# m52363b register map
Vendor: Elmos Semiconductor SE; Series: Integrated Driver; File version: 1.0
CPU: CM23 r1p0, little endian, MPU, no FPU, VTOR, 2 interrupt priority bits, 13 interrupts
Registers are 16-bit, read-write, reset 0x0 unless marked. A register's access mark holds for its fields unless they carry their own. Offsets are from the block's base; [hi:lo] are bit positions; 'fields as' and 'values as' point back to an identical list.

## SYS_STATE — System state module
Base 0x41000400
0x00 VTOR 32-bit reset 0x2000000
  [31:0] val — val bitfield
0x08 TEST_MODE 32-bit ro
  [0] state — state bitfield
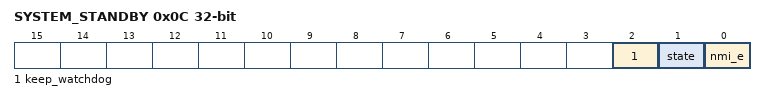
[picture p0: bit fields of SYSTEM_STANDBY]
0x0C SYSTEM_STANDBY 32-bit
  [2] keep_watchdog — keep_watchdog bitfield
  [1] state ro — state bitfield
  [0] nmi_e — nmi_e bitfield
0x10 METAL_CHANGE_CODING 32-bit ro
  [7:0] val — val bitfield
0x14 UDIN 32-bit
  [31:0] val — val bitfield
0x18 DEVICE_ID_L 32-bit ro
  [31:0] val — val bitfield
0x1C DEVICE_ID_H 32-bit ro
  [31:0] val — val bitfield

## RESET_CTRL — Reset control module
Base 0x41000500
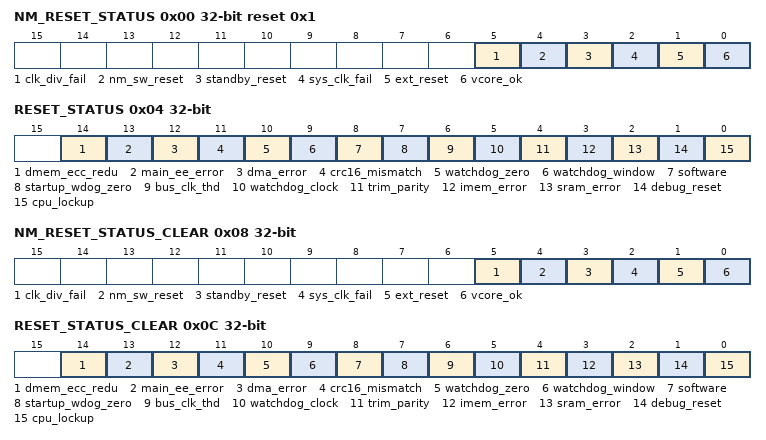
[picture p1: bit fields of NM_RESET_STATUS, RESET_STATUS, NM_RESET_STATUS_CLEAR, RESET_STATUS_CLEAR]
0x00 NM_RESET_STATUS 32-bit ro reset 0x1
  [5] clk_div_fail — clk_div_fail bitfield
  [4] nm_sw_reset — nm_sw_reset bitfield
  [3] standby_reset — standby_reset bitfield
  [2] sys_clk_fail — sys_clk_fail bitfield
  [1] ext_reset — ext_reset bitfield
  [0] vcore_ok — vcore_ok bitfield
0x04 RESET_STATUS 32-bit ro
  [14] dmem_ecc_redu — dmem_ecc_redu bitfield
  [13] main_ee_error — main_ee_error bitfield
  [12] dma_error — dma_error bitfield
  [11] crc16_mismatch — crc16_mismatch bitfield
  [10] watchdog_zero — watchdog_zero bitfield
  [9] watchdog_window — watchdog_window bitfield
  [8] software — software bitfield
  [7] startup_wdog_zero — startup_wdog_zero bitfield
  [6] bus_clk_thd — bus_clk_thd bitfield
  [5] watchdog_clock — watchdog_clock bitfield
  [4] trim_parity — trim_parity bitfield
  [3] imem_error — imem_error bitfield
  [2] sram_error — sram_error bitfield
  [1] debug_reset — debug_reset bitfield
  [0] cpu_lockup — cpu_lockup bitfield
0x08 NM_RESET_STATUS_CLEAR 32-bit wo reset not defined
  fields as NM_RESET_STATUS
0x0C RESET_STATUS_CLEAR 32-bit wo reset not defined
  fields as RESET_STATUS
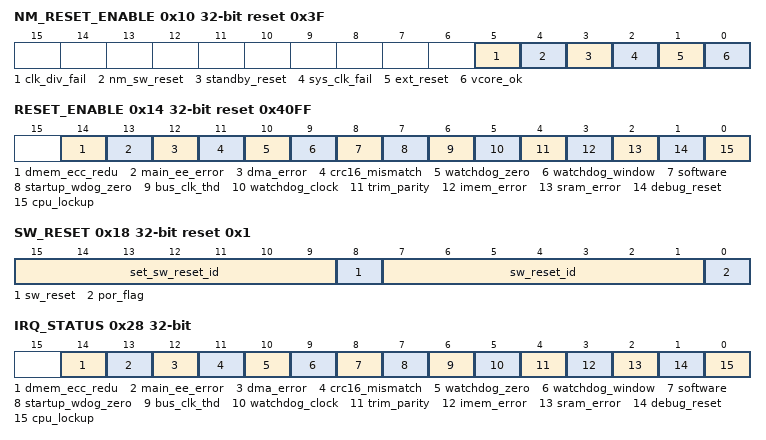
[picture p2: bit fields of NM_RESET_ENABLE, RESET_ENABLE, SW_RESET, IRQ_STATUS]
0x10 NM_RESET_ENABLE 32-bit ro reset 0x3F
  fields as NM_RESET_STATUS
0x14 RESET_ENABLE 32-bit reset 0x40FF
  fields as RESET_STATUS
0x18 SW_RESET 32-bit reset 0x1 (reset mask 0xFF)
  [15:9] set_sw_reset_id wo — set_sw_reset_id bitfield
  [8] sw_reset wo — sw_reset bitfield
  [7:1] sw_reset_id ro — sw_reset_id bitfield
  [0] por_flag ro — por_flag bitfield
0x20 NM_SW_RESET 32-bit wo reset not defined
  [15:0] cookie — cookie bitfield
0x24 VERSION 32-bit ro reset 0x2
  [31:0] version — version bitfield
0x28 IRQ_STATUS 32-bit
  fields as RESET_STATUS
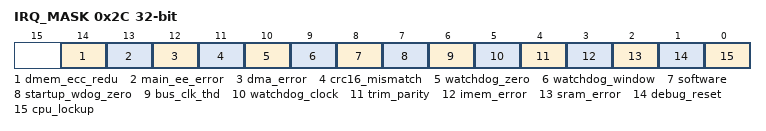
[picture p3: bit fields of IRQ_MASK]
0x2C IRQ_MASK 32-bit
  fields as RESET_STATUS
0x30 IRQ_VENABLE 32-bit wo reset not defined
  [3:0] vno — vno bitfield
0x34 IRQ_VDISABLE 32-bit wo reset not defined
  [3:0] vno — vno bitfield
0x38 IRQ_VMAX 32-bit reset 0xF
  [3:0] vmax — vmax bitfield
0x3C IRQ_VNO 32-bit reset 0xF
  [3:0] vno — vno bitfield

## MOD_SEC_S — This instance contains registers for (core system level) module secure access protection.
Base 0x45000010
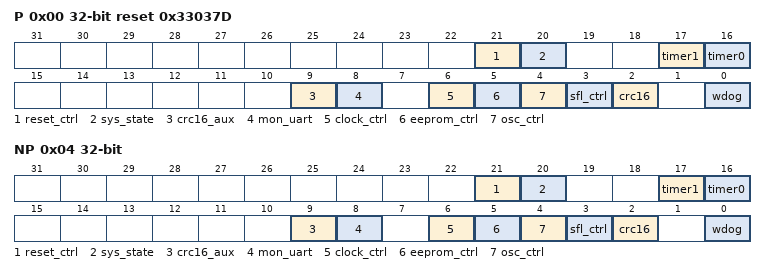
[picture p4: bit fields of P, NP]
0x00 P 32-bit reset 0x33037D
  [21] reset_ctrl — reset_ctrl bitfield
  [20] sys_state — sys_state bitfield
  [17] timer1 — timer1 bitfield
  [16] timer0 — timer0 bitfield
  [9] crc16_aux — crc16_aux bitfield
  [8] mon_uart — mon_uart bitfield
  [6] clock_ctrl — clock_ctrl bitfield
  [5] eeprom_ctrl — eeprom_ctrl bitfield
  [4] osc_ctrl — osc_ctrl bitfield
  [3] sfl_ctrl — sfl_ctrl bitfield
  [2] crc16 — crc16 bitfield
  [0] wdog — wdog bitfield
0x04 NP 32-bit
  fields as P

## MOD_SEC_CORE_S — This instance contains registers for (core level) module secure access protection.
Base 0x45000018
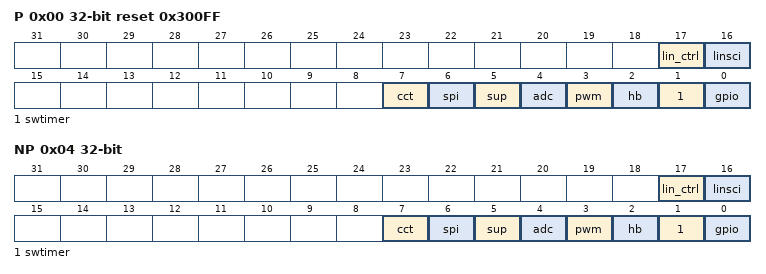
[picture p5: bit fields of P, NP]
0x00 P 32-bit reset 0x300FF
  [17] lin_ctrl — lin_ctrl bitfield
  [16] linsci — linsci bitfield
  [7] cct — cct bitfield
  [6] spi — spi bitfield
  [5] sup — sup bitfield
  [4] adc — adc bitfield
  [3] pwm — pwm bitfield
  [2] hb — hb bitfield
  [1] swtimer — swtimer bitfield
  [0] gpio — gpio bitfield
0x04 NP 32-bit
  fields as P
